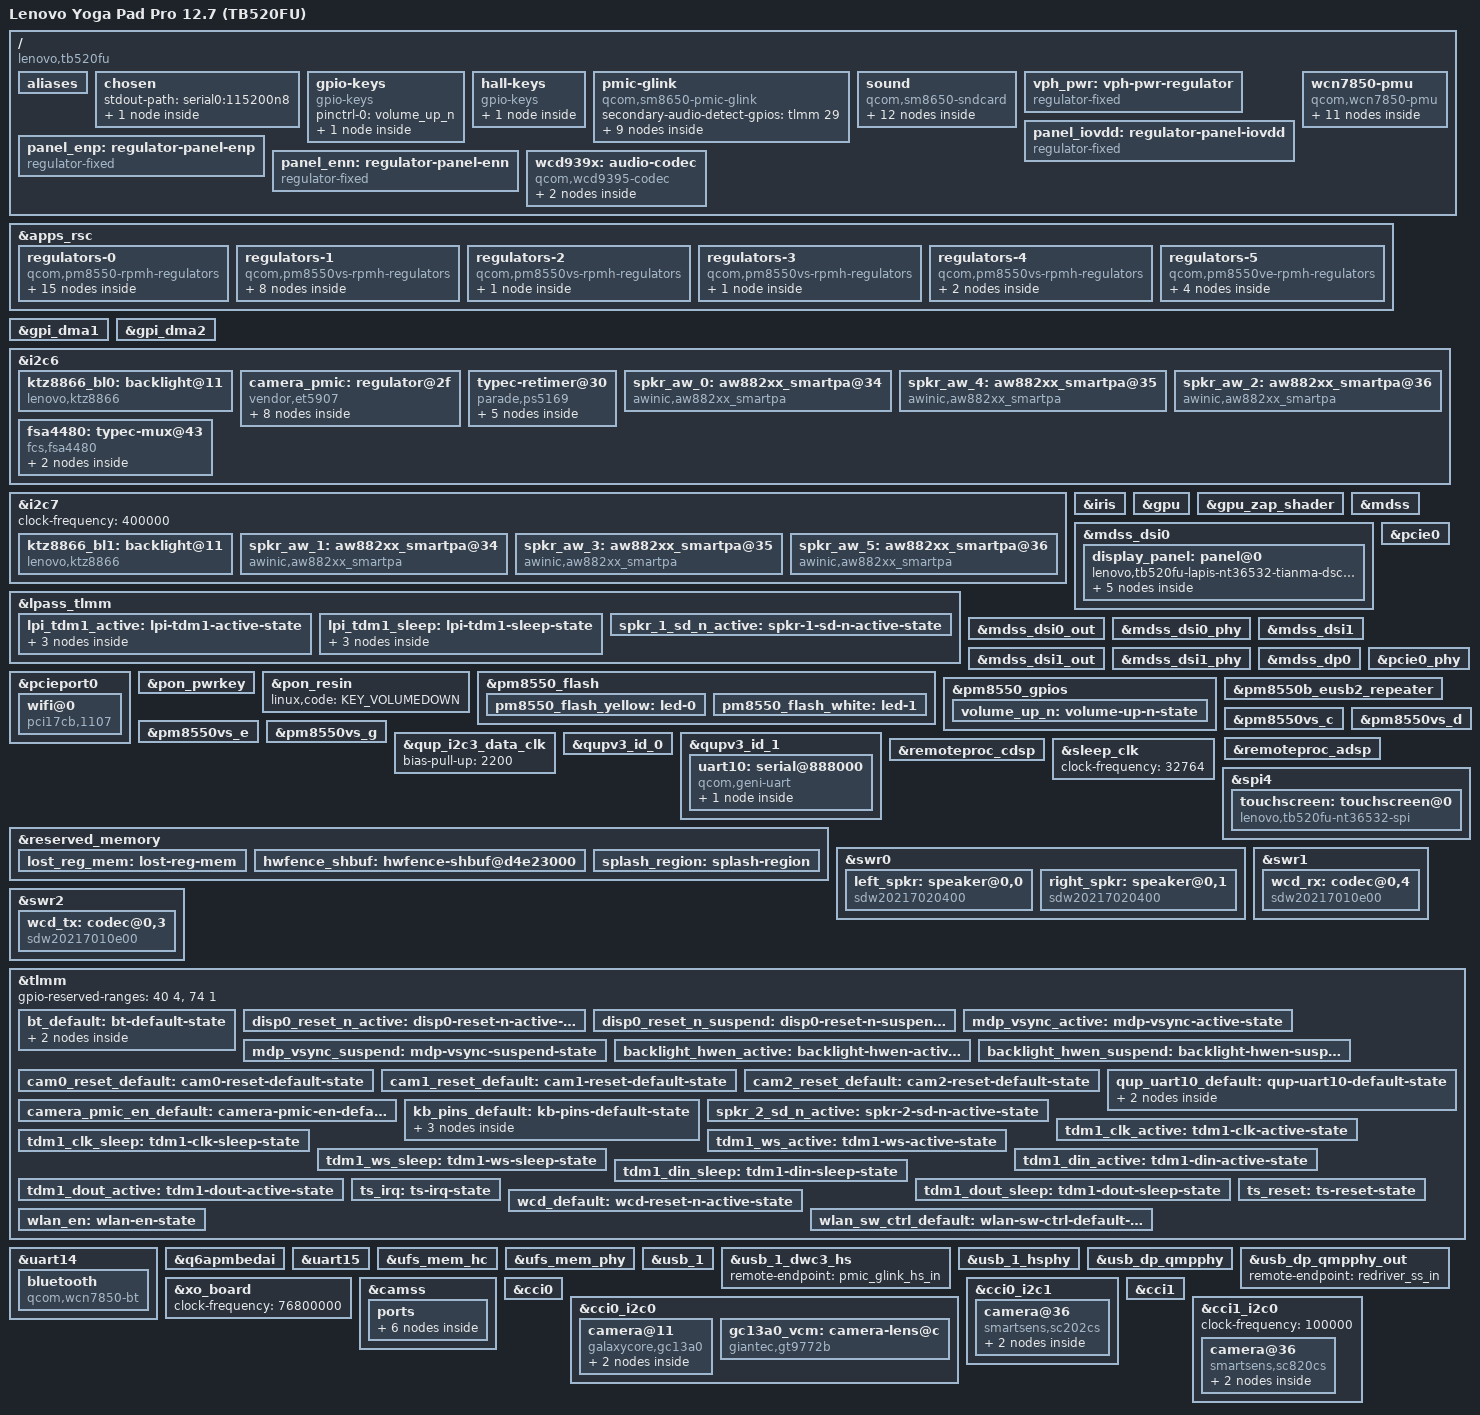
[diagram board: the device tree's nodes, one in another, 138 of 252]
// SPDX-License-Identifier: BSD-3-Clause
/*
 * Device Tree for Lenovo Yoga Pad Pro 12.7 / Yoga Tab Plus (TB520FU, "Lapis")
 * Based on Qualcomm SM8650 (Pineapple) and Lenovo TB321FU Mainline Linux port.
 */

/dts-v1/;

#include <dt-bindings/leds/common.h>
#include <dt-bindings/regulator/qcom,rpmh-regulator.h>
#include <dt-bindings/phy/phy.h>
#include "sm8650.dtsi"
#include "pm8550.dtsi"
#include "pm8550b.dtsi"
#define PMK8550VE_SID 8
#include "pm8550ve.dtsi"
#include "pm8550vs.dtsi"
#include "pmk8550.dtsi"

/delete-node/ &rmtfs_mem;
/delete-node/ &hwfence_shbuf;
/delete-node/ &remoteproc_mpss;
/delete-node/ &qlink_logging_mem;
/delete-node/ &mpss_dsm_mem;
/delete-node/ &mpss_dsm_mem_2;
/delete-node/ &mpss_mem;
/delete-node/ &q6_mpss_dtb_mem;

/ {
	model = "Lenovo Yoga Pad Pro 12.7 (TB520FU)";
	compatible = "lenovo,tb520fu", "qcom,sm8650";
	chassis-type = "tablet";

	aliases {
		serial0 = &uart15;
		serial1 = &uart14;
		serial2 = &uart10;
	};

	chosen {
		#address-cells = <2>;
		#size-cells = <2>;
		ranges;

		stdout-path = "serial0:115200n8";

		/*
		 * Bootloader-initialized continuous splash framebuffer
		 * (2944x1840 @ 120Hz/144Hz native-landscape video-mode panel).
		 * Provides immediate display output via simpledrm before msm_drm takes over.
		 */
		framebuffer0: framebuffer@d5100000 {
			compatible = "simple-framebuffer";
			reg = <0x0 0xd5100000 0x0 0x02b00000>;
			width = <2944>;
			height = <1840>;
			stride = <(2944 * 4)>;
			format = "a8r8g8b8";
			memory-region = <&splash_region>;
		};
	};

	gpio-keys {
		compatible = "gpio-keys";

		pinctrl-0 = <&volume_up_n>;
		pinctrl-names = "default";

		key-volume-up {
			label = "Volume Up";
			linux,code = <KEY_VOLUMEUP>;
			gpios = <&pm8550_gpios 6 GPIO_ACTIVE_LOW>;
			debounce-interval = <15>;
			linux,can-disable;
			wakeup-source;
		};
	};

	/* Hall sensors for folio cover / stand detection (GPIO 177 & GPIO 182) */
	hall-keys {
		compatible = "gpio-keys";

		switch-hall0 {
			label = "Hall Sensor 0";
			linux,input-type = <EV_SW>;
			linux,code = <SW_TABLET_MODE>;
			gpios = <&tlmm 177 GPIO_ACTIVE_LOW>;
			debounce-interval = <20>;
			wakeup-source;
		};
	};

	/* TB520FU has a single USB-C 3.2 Gen 1 port (connector@0) */
	pmic-glink {
		compatible = "qcom,sm8650-pmic-glink",
			     "qcom,sm8550-pmic-glink",
			     "qcom,pmic-glink";
		#address-cells = <1>;
		#size-cells = <0>;
		secondary-audio-detect-gpios = <&tlmm 29 GPIO_ACTIVE_HIGH>;

		connector@0 {
			compatible = "usb-c-connector";
			reg = <0>;

			power-role = "dual";
			data-role = "dual";
			self-powered;

			ports {
				#address-cells = <1>;
				#size-cells = <0>;

				port@0 {
					reg = <0>;

					pmic_glink_hs_in: endpoint {
						remote-endpoint = <&usb_1_dwc3_hs>;
					};
				};

				port@1 {
					reg = <1>;

					pmic_glink_ss_in: endpoint {
						remote-endpoint = <&redriver_ss_out>;
					};
				};

				port@2 {
					reg = <2>;
					#address-cells = <1>;
					#size-cells = <0>;

					pmic_glink_sbu: endpoint@0 {
						reg = <0>;
						remote-endpoint = <&fsa4480_sbu_mux>;
					};

					pmic_glink_sbu_codec: endpoint@1 {
						reg = <1>;
						remote-endpoint = <&wcd_codec_headset_in>;
					};
				};
			};
		};
	};

	sound {
		compatible = "qcom,sm8650-sndcard", "qcom,sm8450-sndcard";
		model = "Lenovo-YogaPadPro-TB520FU";
		pinctrl-names = "default", "sleep";
		pinctrl-0 = <&tdm1_clk_active>, <&tdm1_ws_active>,
			    <&tdm1_din_active>, <&tdm1_dout_active>;
		pinctrl-1 = <&tdm1_clk_sleep>, <&tdm1_ws_sleep>,
			    <&tdm1_din_sleep>, <&tdm1_dout_sleep>;
		audio-routing = "IN1_HPHL", "HPHL_OUT",
				"IN2_HPHR", "HPHR_OUT",
				"AMIC1", "MIC BIAS1",
				"AMIC2", "MIC BIAS2",
				"AMIC3", "MIC BIAS3",
				"AMIC4", "MIC BIAS3",
				"AMIC5", "MIC BIAS4",
				"TX SWR_INPUT0", "ADC1_OUTPUT",
				"TX SWR_INPUT1", "ADC2_OUTPUT",
				"TX SWR_INPUT2", "ADC3_OUTPUT",
				"TX SWR_INPUT3", "ADC4_OUTPUT";

		wcd-playback-dai-link {
			link-name = "WCD Playback";

			cpu {
				sound-dai = <&q6apmbedai RX_CODEC_DMA_RX_0>;
			};

			codec {
				sound-dai = <&wcd939x 0>, <&swr1 0>, <&lpass_rxmacro 0>;
			};

			platform {
				sound-dai = <&q6apm>;
			};
		};

		wcd-capture-dai-link {
			link-name = "WCD Capture";

			cpu {
				sound-dai = <&q6apmbedai TX_CODEC_DMA_TX_3>;
			};

			codec {
				sound-dai = <&wcd939x 1>, <&swr2 0>, <&lpass_txmacro 0>;
			};

			platform {
				sound-dai = <&q6apm>;
			};
		};

		/* 6x Awinic AW88261 SmartPA speaker array (3 on I2C6 + 3 on I2C7) */
		aw-spk-dai-link {
			link-name = "AW882xx Playback";

			cpu {
				sound-dai = <&q6apmbedai SECONDARY_TDM_RX_0>;
			};

			codec {
				sound-dai = <&spkr_aw_0>, <&spkr_aw_1>,
					    <&spkr_aw_2>, <&spkr_aw_3>,
					    <&spkr_aw_4>, <&spkr_aw_5>;
			};

			platform {
				sound-dai = <&q6apm>;
			};
		};
	};

	vph_pwr: vph-pwr-regulator {
		compatible = "regulator-fixed";

		regulator-name = "vph_pwr";
		regulator-min-microvolt = <3700000>;
		regulator-max-microvolt = <3700000>;

		regulator-always-on;
		regulator-boot-on;
	};

	panel_iovdd: regulator-panel-iovdd {
		compatible = "regulator-fixed";
		regulator-name = "panel_iovdd";
		regulator-min-microvolt = <1800000>;
		regulator-max-microvolt = <1800000>;
		gpio = <&pm8550ve_gpios 8 GPIO_ACTIVE_HIGH>;
		enable-active-high;
	};

	panel_enp: regulator-panel-enp {
		compatible = "regulator-fixed";
		regulator-name = "panel_enp";
		gpio = <&tlmm 72 GPIO_ACTIVE_HIGH>;
		enable-active-high;
	};

	panel_enn: regulator-panel-enn {
		compatible = "regulator-fixed";
		regulator-name = "panel_enn";
		gpio = <&tlmm 73 GPIO_ACTIVE_HIGH>;
		enable-active-high;
	};

	wcd939x: audio-codec {
		compatible = "qcom,wcd9395-codec", "qcom,wcd9390-codec";

		pinctrl-0 = <&wcd_default>;
		pinctrl-names = "default";

		qcom,micbias1-microvolt = <1800000>;
		qcom,micbias2-microvolt = <1800000>;
		qcom,micbias3-microvolt = <1800000>;
		qcom,micbias4-microvolt = <1800000>;
		qcom,mbhc-buttons-vthreshold-microvolt = <75000 150000 237000 500000 500000 500000 500000 500000>;
		qcom,mbhc-headset-vthreshold-microvolt = <1700000>;
		qcom,mbhc-headphone-vthreshold-microvolt = <50000>;
		qcom,rx-device = <&wcd_rx>;
		qcom,tx-device = <&wcd_tx>;

		reset-gpios = <&tlmm 107 GPIO_ACTIVE_LOW>;

		vdd-buck-supply = <&vreg_l15b_1p8>;
		vdd-rxtx-supply = <&vreg_l15b_1p8>;
		vdd-io-supply = <&vreg_l15b_1p8>;
		vdd-mic-bias-supply = <&vreg_bob1>;

		#sound-dai-cells = <1>;

		mode-switch;
		orientation-switch;

		port {
			#address-cells = <1>;
			#size-cells = <0>;

			wcd_codec_headset_in: endpoint@0 {
				reg = <0>;
				remote-endpoint = <&pmic_glink_sbu_codec>;
			};
		};
	};

	wcn7850-pmu {
		compatible = "qcom,wcn7850-pmu";

		pinctrl-names = "default";
		pinctrl-0 = <&wlan_en>, <&bt_default>, <&wlan_sw_ctrl_default>;

		wlan-enable-gpios = <&tlmm 16 GPIO_ACTIVE_HIGH>;
		bt-enable-gpios = <&tlmm 17 GPIO_ACTIVE_HIGH>;

		vdd-supply = <&vreg_s4i_0p85>;
		vddio-supply = <&vreg_l15b_1p8>;
		vddio1p2-supply = <&vreg_l3c_1p2>;
		vddaon-supply = <&vreg_s2c_0p8>;
		vdddig-supply = <&vreg_s3c_0p9>;
		vddrfa1p2-supply = <&vreg_s1c_1p2>;
		vddrfa1p8-supply = <&vreg_s6c_1p8>;

		clocks = <&rpmhcc RPMH_RF_CLK1>;

		regulators {
			vreg_pmu_rfa_cmn: ldo0 {
				regulator-name = "vreg_pmu_rfa_cmn";
			};

			vreg_pmu_aon_0p59: ldo1 {
				regulator-name = "vreg_pmu_aon_0p59";
			};

			vreg_pmu_wlcx_0p8: ldo2 {
				regulator-name = "vreg_pmu_wlcx_0p8";
			};

			vreg_pmu_wlmx_0p85: ldo3 {
				regulator-name = "vreg_pmu_wlmx_0p85";
			};

			vreg_pmu_btcmx_0p85: ldo4 {
				regulator-name = "vreg_pmu_btcmx_0p85";
			};

			vreg_pmu_rfa_0p8: ldo5 {
				regulator-name = "vreg_pmu_rfa_0p8";
			};

			vreg_pmu_rfa_1p2: ldo6 {
				regulator-name = "vreg_pmu_rfa_1p2";
			};

			vreg_pmu_rfa_1p8: ldo7 {
				regulator-name = "vreg_pmu_rfa_1p8";
			};

			vreg_pmu_pcie_0p9: ldo8 {
				regulator-name = "vreg_pmu_pcie_0p9";
			};

			vreg_pmu_pcie_1p8: ldo9 {
				regulator-name = "vreg_pmu_pcie_1p8";
			};
		};
	};
};

&apps_rsc {
	regulators-0 {
		compatible = "qcom,pm8550-rpmh-regulators";

		vdd-bob1-supply = <&vph_pwr>;
		vdd-bob2-supply = <&vph_pwr>;
		vdd-l1-l4-l10-supply = <&vreg_s6c_1p8>;
		vdd-l2-l13-l14-supply = <&vreg_bob1>;
		vdd-l3-supply = <&vreg_s1c_1p2>;
		vdd-l5-l16-supply = <&vreg_bob1>;
		vdd-l6-l7-supply = <&vreg_bob1>;
		vdd-l8-l9-supply = <&vreg_bob1>;
		vdd-l11-supply = <&vreg_s1c_1p2>;
		vdd-l12-supply = <&vreg_s6c_1p8>;
		vdd-l15-supply = <&vreg_s6c_1p8>;
		vdd-l17-supply = <&vreg_bob2>;

		qcom,pmic-id = "b";

		vreg_bob1: bob1 {
			regulator-name = "vreg_bob1";
			regulator-min-microvolt = <3296000>;
			regulator-max-microvolt = <3960000>;
			regulator-initial-mode = <RPMH_REGULATOR_MODE_HPM>;
		};

		vreg_bob2: bob2 {
			regulator-name = "vreg_bob2";
			regulator-min-microvolt = <2720000>;
			regulator-max-microvolt = <3008000>;
			regulator-initial-mode = <RPMH_REGULATOR_MODE_HPM>;
		};

		vreg_l2b_3p0: ldo2 {
			regulator-name = "vreg_l2b_3p0";
			regulator-min-microvolt = <3008000>;
			regulator-max-microvolt = <3008000>;
			regulator-initial-mode = <RPMH_REGULATOR_MODE_HPM>;
			regulator-allow-set-load;
			regulator-allowed-modes = <RPMH_REGULATOR_MODE_LPM
						   RPMH_REGULATOR_MODE_HPM>;
		};

		vreg_l5b_3p1: ldo5 {
			regulator-name = "vreg_l5b_3p1";
			regulator-min-microvolt = <3104000>;
			regulator-max-microvolt = <3104000>;
			regulator-initial-mode = <RPMH_REGULATOR_MODE_HPM>;
			regulator-allow-set-load;
			regulator-allowed-modes = <RPMH_REGULATOR_MODE_LPM
						   RPMH_REGULATOR_MODE_HPM>;
		};

		vreg_l6b_1p8: ldo6 {
			regulator-name = "vreg_l6b_1p8";
			regulator-min-microvolt = <1800000>;
			regulator-max-microvolt = <3008000>;
			regulator-initial-mode = <RPMH_REGULATOR_MODE_HPM>;
			regulator-allow-set-load;
			regulator-allowed-modes = <RPMH_REGULATOR_MODE_LPM
						   RPMH_REGULATOR_MODE_HPM>;
		};

		vreg_l7b_1p8: ldo7 {
			regulator-name = "vreg_l7b_1p8";
			regulator-min-microvolt = <1800000>;
			regulator-max-microvolt = <3008000>;
			regulator-initial-mode = <RPMH_REGULATOR_MODE_HPM>;
		};

		vreg_l8b_1p8: ldo8 {
			regulator-name = "vreg_l8b_1p8";
			regulator-min-microvolt = <1800000>;
			regulator-max-microvolt = <3008000>;
			regulator-initial-mode = <RPMH_REGULATOR_MODE_HPM>;
			regulator-allow-set-load;
			regulator-allowed-modes = <RPMH_REGULATOR_MODE_LPM
						   RPMH_REGULATOR_MODE_HPM>;
		};

		vreg_l10b_1p8: ldo10 {
			regulator-name = "vreg_l10b_1p8";
			regulator-min-microvolt = <1800000>;
			regulator-max-microvolt = <1800000>;
			regulator-initial-mode = <RPMH_REGULATOR_MODE_HPM>;
			regulator-allow-set-load;
			regulator-boot-on;
			regulator-always-on;
			regulator-allowed-modes = <RPMH_REGULATOR_MODE_LPM
						   RPMH_REGULATOR_MODE_HPM>;
		};

		vreg_l11b_1p2: ldo11 {
			regulator-name = "vreg_l11b_1p2";
			regulator-min-microvolt = <1200000>;
			regulator-max-microvolt = <1504000>;
			regulator-initial-mode = <RPMH_REGULATOR_MODE_HPM>;
			regulator-allow-set-load;
			regulator-allowed-modes = <RPMH_REGULATOR_MODE_LPM
						   RPMH_REGULATOR_MODE_HPM>;
		};

		vreg_l12b_1p8: ldo12 {
			regulator-name = "vreg_l12b_1p8";
			regulator-min-microvolt = <1800000>;
			regulator-max-microvolt = <1800000>;
			regulator-initial-mode = <RPMH_REGULATOR_MODE_HPM>;
			regulator-allow-set-load;
			regulator-allowed-modes = <RPMH_REGULATOR_MODE_LPM
						   RPMH_REGULATOR_MODE_HPM>;
		};

		vreg_l13b_3p0: ldo13 {
			regulator-name = "vreg_l13b_3p0";
			regulator-min-microvolt = <3000000>;
			regulator-max-microvolt = <3000000>;
			regulator-initial-mode = <RPMH_REGULATOR_MODE_HPM>;
			regulator-allow-set-load;
			regulator-allowed-modes = <RPMH_REGULATOR_MODE_LPM
						   RPMH_REGULATOR_MODE_HPM>;
		};

		vreg_l14b_3p2: ldo14 {
			regulator-name = "vreg_l14b_3p2";
			regulator-min-microvolt = <3200000>;
			regulator-max-microvolt = <3200000>;
			regulator-initial-mode = <RPMH_REGULATOR_MODE_HPM>;
			regulator-allow-set-load;
			regulator-allowed-modes = <RPMH_REGULATOR_MODE_LPM
						   RPMH_REGULATOR_MODE_HPM>;
		};

		vreg_l15b_1p8: ldo15 {
			regulator-name = "vreg_l15b_1p8";
			regulator-min-microvolt = <1800000>;
			regulator-max-microvolt = <1800000>;
			regulator-initial-mode = <RPMH_REGULATOR_MODE_HPM>;
			regulator-allow-set-load;
			regulator-allowed-modes = <RPMH_REGULATOR_MODE_LPM
						   RPMH_REGULATOR_MODE_HPM>;
		};

		vreg_l16b_2p8: ldo16 {
			regulator-name = "vreg_l16b_2p8";
			regulator-min-microvolt = <2800000>;
			regulator-max-microvolt = <2800000>;
			regulator-initial-mode = <RPMH_REGULATOR_MODE_HPM>;
			regulator-allow-set-load;
			regulator-allowed-modes = <RPMH_REGULATOR_MODE_LPM
						   RPMH_REGULATOR_MODE_HPM>;
		};

		vreg_l17b_2p5: ldo17 {
			regulator-name = "vreg_l17b_2p5";
			regulator-min-microvolt = <2504000>;
			regulator-max-microvolt = <2504000>;
			regulator-initial-mode = <RPMH_REGULATOR_MODE_HPM>;
			regulator-allow-set-load;
			regulator-allowed-modes = <RPMH_REGULATOR_MODE_LPM
						   RPMH_REGULATOR_MODE_HPM>;
		};
	};

	regulators-1 {
		compatible = "qcom,pm8550vs-rpmh-regulators";

		vdd-l1-supply = <&vreg_s1c_1p2>;
		vdd-l2-supply = <&vreg_s1c_1p2>;
		vdd-l3-supply = <&vreg_s1c_1p2>;
		vdd-s1-supply = <&vph_pwr>;
		vdd-s2-supply = <&vph_pwr>;
		vdd-s3-supply = <&vph_pwr>;
		vdd-s4-supply = <&vph_pwr>;
		vdd-s5-supply = <&vph_pwr>;
		vdd-s6-supply = <&vph_pwr>;

		qcom,pmic-id = "c";

		vreg_s1c_1p2: smps1 {
			regulator-name = "vreg_s1c_1p2";
			regulator-min-microvolt = <1256000>;
			regulator-max-microvolt = <1348000>;
			regulator-initial-mode = <RPMH_REGULATOR_MODE_HPM>;
		};

		vreg_s2c_0p8: smps2 {
			regulator-name = "vreg_s2c_0p8";
			regulator-min-microvolt = <852000>;
			regulator-max-microvolt = <1036000>;
			regulator-initial-mode = <RPMH_REGULATOR_MODE_HPM>;
		};

		vreg_s3c_0p9: smps3 {
			regulator-name = "vreg_s3c_0p9";
			regulator-min-microvolt = <976000>;
			regulator-max-microvolt = <1064000>;
			regulator-initial-mode = <RPMH_REGULATOR_MODE_HPM>;
		};

		vreg_s4c_1p2: smps4 {
			regulator-name = "vreg_s4c_1p2";
			regulator-min-microvolt = <1224000>;
			regulator-max-microvolt = <1280000>;
			regulator-initial-mode = <RPMH_REGULATOR_MODE_HPM>;
		};

		vreg_s5c_0p7: smps5 {
			regulator-name = "vreg_s5c_0p7";
			regulator-min-microvolt = <752000>;
			regulator-max-microvolt = <900000>;
			regulator-initial-mode = <RPMH_REGULATOR_MODE_HPM>;
		};

		vreg_s6c_1p8: smps6 {
			regulator-name = "vreg_s6c_1p8";
			regulator-min-microvolt = <1856000>;
			regulator-max-microvolt = <2000000>;
			regulator-initial-mode = <RPMH_REGULATOR_MODE_HPM>;
		};

		vreg_l1c_1p2: ldo1 {
			regulator-name = "vreg_l1c_1p2";
			regulator-min-microvolt = <1200000>;
			regulator-max-microvolt = <1200000>;
			regulator-initial-mode = <RPMH_REGULATOR_MODE_HPM>;
			regulator-allow-set-load;
			regulator-allowed-modes = <RPMH_REGULATOR_MODE_LPM
						   RPMH_REGULATOR_MODE_HPM>;
		};

		vreg_l3c_1p2: ldo3 {
			regulator-name = "vreg_l3c_1p2";
			regulator-min-microvolt = <1200000>;
			regulator-max-microvolt = <1200000>;
			regulator-initial-mode = <RPMH_REGULATOR_MODE_HPM>;
			regulator-allow-set-load;
			regulator-allowed-modes = <RPMH_REGULATOR_MODE_LPM
						   RPMH_REGULATOR_MODE_HPM>;
		};
	};

	regulators-2 {
		compatible = "qcom,pm8550vs-rpmh-regulators";

		vdd-l1-supply = <&vreg_s3c_0p9>;

		qcom,pmic-id = "d";

		vreg_l1d_0p88: ldo1 {
			regulator-name = "vreg_l1d_0p88";
			regulator-min-microvolt = <912000>;
			regulator-max-microvolt = <920000>;
			regulator-initial-mode = <RPMH_REGULATOR_MODE_HPM>;
			regulator-allow-set-load;
			regulator-allowed-modes = <RPMH_REGULATOR_MODE_LPM
						   RPMH_REGULATOR_MODE_HPM>;
		};
	};

	regulators-3 {
		compatible = "qcom,pm8550vs-rpmh-regulators";

		vdd-l3-supply = <&vreg_s3c_0p9>;

		qcom,pmic-id = "e";

		vreg_l3e_0p9: ldo3 {
			regulator-name = "vreg_l3e_0p9";
			regulator-min-microvolt = <880000>;
			regulator-max-microvolt = <920000>;
			regulator-initial-mode = <RPMH_REGULATOR_MODE_HPM>;
			regulator-allow-set-load;
			regulator-allowed-modes = <RPMH_REGULATOR_MODE_LPM
						   RPMH_REGULATOR_MODE_HPM>;
		};
	};

	regulators-4 {
		compatible = "qcom,pm8550vs-rpmh-regulators";

		vdd-l1-supply = <&vreg_s3c_0p9>;
		vdd-l3-supply = <&vreg_s3c_0p9>;

		qcom,pmic-id = "g";

		vreg_l1g_0p91: ldo1 {
			regulator-name = "vreg_l1g_0p91";
			regulator-min-microvolt = <912000>;
			regulator-max-microvolt = <920000>;
			regulator-initial-mode = <RPMH_REGULATOR_MODE_HPM>;
			regulator-allow-set-load;
			regulator-allowed-modes = <RPMH_REGULATOR_MODE_LPM
						   RPMH_REGULATOR_MODE_HPM>;
		};

		vreg_l3g_0p91: ldo3 {
			regulator-name = "vreg_l3g_0p91";
			regulator-min-microvolt = <880000>;
			regulator-max-microvolt = <912000>;
			regulator-initial-mode = <RPMH_REGULATOR_MODE_HPM>;
			regulator-allow-set-load;
			regulator-allowed-modes = <RPMH_REGULATOR_MODE_LPM
						   RPMH_REGULATOR_MODE_HPM>;
		};
	};

	regulators-5 {
		compatible = "qcom,pm8550ve-rpmh-regulators";

		vdd-l1-supply = <&vreg_s3c_0p9>;
		vdd-l2-supply = <&vreg_s3c_0p9>;
		vdd-l3-supply = <&vreg_s1c_1p2>;
		vdd-s4-supply = <&vph_pwr>;

		qcom,pmic-id = "i";

		vreg_s4i_0p85: smps4 {
			regulator-name = "vreg_s4i_0p85";
			regulator-min-microvolt = <852000>;
			regulator-max-microvolt = <1004000>;
			regulator-initial-mode = <RPMH_REGULATOR_MODE_HPM>;
		};

		vreg_l1i_0p88: ldo1 {
			regulator-name = "vreg_l1i_0p88";
			regulator-min-microvolt = <880000>;
			regulator-max-microvolt = <912000>;
			regulator-initial-mode = <RPMH_REGULATOR_MODE_HPM>;
			regulator-allow-set-load;
			regulator-allowed-modes = <RPMH_REGULATOR_MODE_LPM
						   RPMH_REGULATOR_MODE_HPM>;
		};

		vreg_l2i_0p88: ldo2 {
			regulator-name = "vreg_l2i_0p88";
			regulator-min-microvolt = <880000>;
			regulator-max-microvolt = <912000>;
			regulator-initial-mode = <RPMH_REGULATOR_MODE_HPM>;
			regulator-allow-set-load;
			regulator-allowed-modes = <RPMH_REGULATOR_MODE_LPM
						   RPMH_REGULATOR_MODE_HPM>;
		};

		vreg_l3i_1p2: ldo3 {
			regulator-name = "vreg_l3i_0p91";
			regulator-min-microvolt = <1200000>;
			regulator-max-microvolt = <1200000>;
			regulator-initial-mode = <RPMH_REGULATOR_MODE_HPM>;
			regulator-allow-set-load;
			regulator-allowed-modes = <RPMH_REGULATOR_MODE_LPM
						   RPMH_REGULATOR_MODE_HPM>;
		};
	};
};

&gpi_dma1 {
	status = "okay";
};

&gpi_dma2 {
	status = "okay";
};

/*
 * Mainline &i2c6 = i2c@a98000 (Downstream i2c14):
 *   - Primary KTZ8866 backlight (@11, HWEN GPIO 82)
 *   - 3x Awinic AW88261 SmartPA (@34 ch0, @35 ch4, @36 ch2, reset GPIO 128)
 *   - USB-C muxes (fsa4480 @42/@43) & PS5169 retimer (@30)
 *   - Camera PMIC WL2868C (@2f, enable GPIO 5)
 */
&i2c6 {
	status = "okay";

	ktz8866_bl0: backlight@11 {
		compatible = "lenovo,ktz8866", "kinetic,ktz8866";
		reg = <0x11>;

		pinctrl-0 = <&backlight_hwen_active>;
		pinctrl-1 = <&backlight_hwen_suspend>;
		pinctrl-names = "default", "sleep";
		enable-gpios = <&tlmm 82 GPIO_ACTIVE_HIGH>;

		kinetic,enable-lcd-bias;
		lenovo,companion-backlight = <&ktz8866_bl1>;
		current-num-sinks = <6>;
		max-brightness = <2047>;
		default-brightness-level = <1027>;
	};

	camera_pmic: regulator@2f {
		compatible = "vendor,et5907", "willsemi,wl2868c";
		reg = <0x2f>;

		pinctrl-0 = <&camera_pmic_en_default>;
		pinctrl-names = "default";
		enable-gpios = <&tlmm 5 GPIO_ACTIVE_HIGH>;

		vin1-supply = <&vreg_s6c_1p8>;
		vin2-supply = <&vreg_bob1>;
		vin3-supply = <&vreg_l10b_1p8>;

		regulators {
			cam_ldo1_1p2: ldo1 {
				regulator-name = "cam_ldo1_1p2";
				regulator-min-microvolt = <1200000>;
				regulator-max-microvolt = <1200000>;
			};

			cam_ldo2_1p31: ldo2 {
				regulator-name = "cam_ldo2_1p31";
				regulator-min-microvolt = <1312000>;
				regulator-max-microvolt = <1312000>;
			};

			cam_ldo3_1p8: ldo3 {
				regulator-name = "cam_ldo3_1p8";
				regulator-min-microvolt = <1800000>;
				regulator-max-microvolt = <2784000>;
			};

			cam_ldo4_2p8: ldo4 {
				regulator-name = "cam_ldo4_2p8";
				regulator-min-microvolt = <2800000>;
				regulator-max-microvolt = <2800000>;
			};

			cam_ldo5_2p78: ldo5 {
				regulator-name = "cam_ldo5_2p78";
				regulator-min-microvolt = <2784000>;
				regulator-max-microvolt = <2784000>;
				regulator-enable-ramp-delay = <10000>;
			};

			cam_ldo6_2p78: ldo6 {
				regulator-name = "cam_ldo6_2p78";
				regulator-min-microvolt = <2784000>;
				regulator-max-microvolt = <2784000>;
			};

			cam_ldo7_2p024: ldo7 {
				regulator-name = "cam_ldo7_2p024";
				regulator-min-microvolt = <2024000>;
				regulator-max-microvolt = <2024000>;
			};
		};
	};

	typec-retimer@30 {
		compatible = "parade,ps5169", "hq_redriver,ps5169";
		reg = <0x30>;

		retimer-switch;
		orientation-switch;

		ports {
			#address-cells = <1>;
			#size-cells = <0>;

			port@0 {
				reg = <0>;

				redriver_ss_out: endpoint {
					remote-endpoint = <&pmic_glink_ss_in>;
				};
			};

			port@1 {
				reg = <1>;

				redriver_ss_in: endpoint {
					data-lanes = <3 2 1 0>;
					remote-endpoint = <&usb_dp_qmpphy_out>;
				};
			};
		};
	};

	spkr_aw_0: aw882xx_smartpa@34 {
		compatible = "awinic,aw882xx_smartpa";
		reg = <0x34>;
		#sound-dai-cells = <0>;
		aw-cali-mode = "none";
		aw-re-max = <0x7530>;
		aw-re-min = <0x0fa0>;
		rename-flag = <1>;
		sound-channel = <0>;
		sync-load = <1>;
		one_rst_flag = <1>;
		reset-gpio = <&tlmm 128 GPIO_ACTIVE_HIGH>;
	};

	spkr_aw_4: aw882xx_smartpa@35 {
		compatible = "awinic,aw882xx_smartpa";
		reg = <0x35>;
		#sound-dai-cells = <0>;
		aw-cali-mode = "none";
		aw-re-max = <0x7530>;
		aw-re-min = <0x0fa0>;
		rename-flag = <1>;
		sound-channel = <4>;
		sync-load = <1>;
		one_rst_flag = <1>;
		reset-gpio = <&tlmm 128 GPIO_ACTIVE_HIGH>;
	};

	spkr_aw_2: aw882xx_smartpa@36 {
		compatible = "awinic,aw882xx_smartpa";
		reg = <0x36>;
		#sound-dai-cells = <0>;
		aw-cali-mode = "none";
		aw-re-max = <0x7530>;
		aw-re-min = <0x0fa0>;
		rename-flag = <1>;
		sound-channel = <2>;
		sync-load = <1>;
		one_rst_flag = <1>;
		reset-gpio = <&tlmm 128 GPIO_ACTIVE_HIGH>;
	};

	fsa4480: typec-mux@43 {
		compatible = "fcs,fsa4480";
		reg = <0x43>;

		vcc-supply = <&vreg_l15b_1p8>;

		mode-switch;
		orientation-switch;

		port {
			fsa4480_sbu_mux: endpoint {
				remote-endpoint = <&pmic_glink_sbu>;
			};
		};
	};
};

/*
 * Mainline &i2c7 = i2c@a9c000 (Downstream i2c15):
 *   - Secondary KTZ8866 backlight (@11)
 *   - 3x Awinic AW88261 SmartPA (@34 ch1, @35 ch3, @36 ch5, reset GPIO 28)
 */
&i2c7 {
	status = "okay";
	clock-frequency = <400000>;

	ktz8866_bl1: backlight@11 {
		compatible = "lenovo,ktz8866", "kinetic,ktz8866";
		reg = <0x11>;

		lenovo,secondary-chip;
		current-num-sinks = <6>;
		max-brightness = <2047>;
		default-brightness-level = <1027>;
	};

	spkr_aw_1: aw882xx_smartpa@34 {
		compatible = "awinic,aw882xx_smartpa";
		reg = <0x34>;
		#sound-dai-cells = <0>;
		aw-cali-mode = "none";
		aw-re-max = <0x7530>;
		aw-re-min = <0x0fa0>;
		rename-flag = <1>;
		sound-channel = <1>;
		sync-load = <1>;
		one_rst_flag = <2>;
		reset-gpio = <&tlmm 28 GPIO_ACTIVE_HIGH>;
	};

	spkr_aw_3: aw882xx_smartpa@35 {
		compatible = "awinic,aw882xx_smartpa";
		reg = <0x35>;
		#sound-dai-cells = <0>;
		aw-cali-mode = "none";
		aw-re-max = <0x7530>;
		aw-re-min = <0x0fa0>;
		rename-flag = <1>;
		sound-channel = <3>;
		sync-load = <1>;
		one_rst_flag = <2>;
		reset-gpio = <&tlmm 28 GPIO_ACTIVE_HIGH>;
	};

	spkr_aw_5: aw882xx_smartpa@36 {
		compatible = "awinic,aw882xx_smartpa";
		reg = <0x36>;
		#sound-dai-cells = <0>;
		aw-cali-mode = "none";
		aw-re-max = <0x7530>;
		aw-re-min = <0x0fa0>;
		rename-flag = <1>;
		sound-channel = <5>;
		sync-load = <1>;
		one_rst_flag = <2>;
		reset-gpio = <&tlmm 28 GPIO_ACTIVE_HIGH>;
	};
};

&iris {
	status = "okay";
};

&gpu {
	status = "okay";
};

&gpu_zap_shader {
	firmware-name = "qcom/sm8650/lenovo/tb520fu/gen70900_zap.mbn";
};

&lpass_tlmm {
	lpi_tdm1_active: lpi-tdm1-active-state {
		clk-pins {
			pins = "gpio6";
			function = "i2s1_clk";
			drive-strength = <8>;
			bias-disable;
			output-high;
		};

		ws-pins {
			pins = "gpio7";
			function = "i2s1_ws";
			drive-strength = <8>;
			bias-disable;
			output-high;
		};

		data-pins {
			pins = "gpio8", "gpio9";
			function = "i2s1_data";
			drive-strength = <8>;
			bias-disable;
			output-high;
		};
	};

	lpi_tdm1_sleep: lpi-tdm1-sleep-state {
		clk-pins {
			pins = "gpio6";
			function = "i2s1_clk";
			drive-strength = <2>;
			bias-pull-down;
			input-enable;
		};

		ws-pins {
			pins = "gpio7";
			function = "i2s1_ws";
			drive-strength = <2>;
			bias-pull-down;
			input-enable;
		};

		data-pins {
			pins = "gpio8", "gpio9";
			function = "i2s1_data";
			drive-strength = <2>;
			bias-pull-down;
			input-enable;
		};
	};

	spkr_1_sd_n_active: spkr-1-sd-n-active-state {
		pins = "gpio21";
		function = "gpio";
		drive-strength = <16>;
		bias-disable;
		output-low;
	};
};

&mdss {
	status = "okay";
};

&mdss_dsi0 {
	vdda-supply = <&vreg_l3i_1p2>;
	qcom,dual-dsi-mode;
	qcom,sync-dual-dsi;
	qcom,master-dsi;
	status = "okay";

	display_panel: panel@0 {
		compatible = "lenovo,tb520fu-lapis-nt36532-tianma-dsc-vid",
			     "lenovo,lapis-nt36532-tianma-dsc-vid",
			     "lenovo,tb321fu-kirby-nt36523-csot-dsc-vid",
			     "lenovo,kirby-nt36523-csot-dsc-vid";
		reg = <0>;
		panel-name = "lapis_tianma_nt36532_dsc_3k_video";
		vddio-supply = <&panel_iovdd>;
		enp-supply = <&panel_enp>;
		enn-supply = <&panel_enn>;
		reset-gpios = <&tlmm 133 GPIO_ACTIVE_LOW>;
		pinctrl-names = "default", "sleep";
		pinctrl-0 = <&disp0_reset_n_active>, <&mdp_vsync_active>;
		pinctrl-1 = <&disp0_reset_n_suspend>, <&mdp_vsync_suspend>;
		backlight = <&ktz8866_bl0>;
		rotation = <0>;

		ports {
			#address-cells = <1>;
			#size-cells = <0>;

			port@0 {
				reg = <0>;

				panel_in_0: endpoint {
					remote-endpoint = <&mdss_dsi0_out>;
				};
			};

			port@1 {
				reg = <1>;

				panel_in_1: endpoint {
					remote-endpoint = <&mdss_dsi1_out>;
				};
			};
		};
	};
};

&mdss_dsi0_out {
	data-lanes = <0 1 2 3>;
	remote-endpoint = <&panel_in_0>;
};

&mdss_dsi0_phy {
	vdds-supply = <&vreg_l1i_0p88>;
	phy-type = <PHY_TYPE_DPHY>;
	qcom,mdss-dsi-panel-phy-timings = [00 25 0a 0a 1b 18 0a 0a 0a 02 04 00 1f 0f];

	status = "okay";
};

&mdss_dsi1 {
	vdda-supply = <&vreg_l3i_1p2>;
	qcom,dual-dsi-mode;
	qcom,sync-dual-dsi;
	assigned-clock-parents = <&mdss_dsi0_phy DSI_BYTE_PLL_CLK>,
				 <&mdss_dsi0_phy DSI_PIXEL_PLL_CLK>;

	status = "okay";
};

&mdss_dsi1_out {
	data-lanes = <0 1 2 3>;
	remote-endpoint = <&panel_in_1>;
};

&mdss_dsi1_phy {
	vdds-supply = <&vreg_l1i_0p88>;
	phy-type = <PHY_TYPE_DPHY>;
	qcom,mdss-dsi-panel-phy-timings = [00 25 0a 0a 1b 18 0a 0a 0a 02 04 00 1f 0f];

	status = "okay";
};

&mdss_dp0 {
	status = "okay";
};

&pcie0 {
	wake-gpios = <&tlmm 96 GPIO_ACTIVE_HIGH>;
	perst-gpios = <&tlmm 94 GPIO_ACTIVE_LOW>;

	pinctrl-0 = <&pcie0_default_state>;
	pinctrl-names = "default";

	status = "okay";
};

&pcieport0 {
	wifi@0 {
		compatible = "pci17cb,1107";
		reg = <0x10000 0x0 0x0 0x0 0x0>;

		vddrfacmn-supply = <&vreg_pmu_rfa_cmn>;
		vddaon-supply = <&vreg_pmu_aon_0p59>;
		vddwlcx-supply = <&vreg_pmu_wlcx_0p8>;
		vddwlmx-supply = <&vreg_pmu_wlmx_0p85>;
		vddrfa0p8-supply = <&vreg_pmu_rfa_0p8>;
		vddrfa1p2-supply = <&vreg_pmu_rfa_1p2>;
		vddrfa1p8-supply = <&vreg_pmu_rfa_1p8>;
		vddpcie0p9-supply = <&vreg_pmu_pcie_0p9>;
		vddpcie1p8-supply = <&vreg_pmu_pcie_1p8>;
	};
};

&pcie0_phy {
	vdda-phy-supply = <&vreg_l1i_0p88>;
	vdda-pll-supply = <&vreg_l3i_1p2>;

	status = "okay";
};

&pon_pwrkey {
	status = "okay";
};

&pon_resin {
	linux,code = <KEY_VOLUMEDOWN>;

	status = "okay";
};

&pm8550_flash {
	status = "okay";

	pm8550_flash_yellow: led-0 {
		function = LED_FUNCTION_FLASH;
		color = <LED_COLOR_ID_YELLOW>;
		led-sources = <1>, <4>;
		led-max-microamp = <500000>;
		flash-max-microamp = <2000000>;
		flash-max-timeout-us = <1280000>;
		function-enumerator = <0>;
	};

	pm8550_flash_white: led-1 {
		function = LED_FUNCTION_FLASH;
		color = <LED_COLOR_ID_WHITE>;
		led-sources = <2>, <3>;
		led-max-microamp = <500000>;
		flash-max-microamp = <2000000>;
		flash-max-timeout-us = <1280000>;
		function-enumerator = <1>;
	};
};

&pm8550_gpios {
	volume_up_n: volume-up-n-state {
		pins = "gpio6";
		function = "normal";
		bias-pull-up;
		input-enable;
		power-source = <1>;
	};
};

&pm8550b_eusb2_repeater {
	vdd18-supply = <&vreg_l15b_1p8>;
	vdd3-supply = <&vreg_l5b_3p1>;
	qcom,tune-usb2-amplitude = /bits/ 8 <0x0d>;
	qcom,tune-usb2-disc-thres = /bits/ 8 <0x06>;
	qcom,tune-usb2-preem = /bits/ 8 <0x07>;
	qcom,squelch-detector = <(-4000)>;
};

&pm8550vs_c {
	status = "okay";
};

&pm8550vs_d {
	status = "okay";
};

&pm8550vs_e {
	status = "okay";
};

&pm8550vs_g {
	status = "okay";
};

&qup_i2c3_data_clk {
	bias-pull-up = <2200>;
};

&qupv3_id_0 {
	status = "okay";
};

/*
 * Enable GENI QUPv3 Wrapper 2 (qupv3_id_1 @ 0x8c0000) and define
 * uart10 (serial@888000, SE2) for the Lenovo Pogo-Pin Magnetic Keyboard.
 */
&qupv3_id_1 {
	status = "okay";

	uart10: serial@888000 {
		compatible = "qcom,geni-uart";
		reg = <0 0x00888000 0 0x4000>;
		interrupts = <GIC_SPI 584 IRQ_TYPE_LEVEL_HIGH 0>;
		clocks = <&gcc GCC_QUPV3_WRAP2_S2_CLK>;
		clock-names = "se";

		interconnects = <&clk_virt MASTER_QUP_CORE_2 QCOM_ICC_TAG_ALWAYS
				 &clk_virt SLAVE_QUP_CORE_2 QCOM_ICC_TAG_ALWAYS>,
				<&gem_noc MASTER_APPSS_PROC QCOM_ICC_TAG_ACTIVE_ONLY
				 &config_noc SLAVE_QUP_2 QCOM_ICC_TAG_ACTIVE_ONLY>;
		interconnect-names = "qup-core",
				     "qup-config";

		power-domains = <&rpmhpd RPMHPD_CX>;
		operating-points-v2 = <&qup_opp_table_100mhz>;

		pinctrl-0 = <&qup_uart10_default>;
		pinctrl-names = "default";

		status = "okay";

		keyboard {
			compatible = "lenovo,tb520fu-keyboard",
				     "lenovo,lenovo_keyboard";

			pinctrl-0 = <&kb_pins_default>;
			pinctrl-names = "default";

			power-en-gpios = <&tlmm 173 GPIO_ACTIVE_HIGH>;
			tx-en-gpios = <&tlmm 119 GPIO_ACTIVE_HIGH>;
			plug-gpios = <&tlmm 198 GPIO_ACTIVE_HIGH>;
			uart-wake-gpios = <&tlmm 171 GPIO_ACTIVE_HIGH>;
			pupd-gpios = <&tlmm 180 GPIO_ACTIVE_HIGH>;
			lid-gpios = <&tlmm 200 GPIO_ACTIVE_HIGH>;
		};
	};
};

&remoteproc_adsp {
	firmware-name = "qcom/sm8650/lenovo/tb520fu/adsp.mdt",
			"qcom/sm8650/lenovo/tb520fu/adsp_dtb.mdt";

	status = "okay";
};

&remoteproc_cdsp {
	firmware-name = "qcom/sm8650/lenovo/tb520fu/cdsp.mdt",
			"qcom/sm8650/lenovo/tb520fu/cdsp_dtb.mdt";

	status = "okay";
};

&reserved_memory {
	lost_reg_mem: lost-reg-mem {
		reg = <0 0x9b09c000 0 0x4000>;
		no-map;
	};

	hwfence_shbuf: hwfence-shbuf@d4e23000 {
		reg = <0 0xd4e23000 0 0x2dd000>;
		no-map;
	};

	splash_region: splash-region {
		label = "cont_splash_region";
		reg = <0 0xd5100000 0 0x2b00000>;
		no-map;
	};
};

&sleep_clk {
	clock-frequency = <32764>;
};

/*
 * Mainline &spi4 = spi@a90000 (Downstream spi12):
 *   Novatek NT36532 Touchscreen + Lenovo Tab Pen Plus Stylus (1840x2944)
 */
&spi4 {
	status = "okay";

	touchscreen: touchscreen@0 {
		compatible = "lenovo,tb520fu-nt36532-spi",
			     "lenovo,tb321fu-nt36523n-spi",
			     "novatek,nt36523n-spi",
			     "novatek,NVT-ts-spi";
		reg = <0>;

		reset-gpios = <&tlmm 161 GPIO_ACTIVE_HIGH>;
		irq-gpio = <&tlmm 162 GPIO_ACTIVE_LOW>;
		novatek,reset-gpio = <&tlmm 161 GPIO_ACTIVE_HIGH>;
		novatek,irq-gpio = <&tlmm 162 GPIO_ACTIVE_LOW>;

		vdd-supply = <&vreg_l14b_3p2>;
		vio-supply = <&vreg_l12b_1p8>;

		spi-max-frequency = <9600000>;
		novatek,swrst-n8-addr = <0x03f0fe>;
		novatek,spi-rd-fast-addr = <0x03f310>;
		novatek,pen-support;

		touchscreen-size-x = <18400>;
		touchscreen-size-y = <29440>;
		touchscreen-swapped-x-y;
		touchscreen-inverted-y;

		firmware-name = "qcom/sm8650/lenovo/tb520fu/novatek_ts_fw.bin";
		panel = <&display_panel>;

		pinctrl-names = "default";
		pinctrl-0 = <&ts_reset>, <&ts_irq>;
	};
};

&swr0 {
	status = "okay";

	left_spkr: speaker@0,0 {
		compatible = "sdw20217020400";
		reg = <0 0>;
		pinctrl-0 = <&spkr_1_sd_n_active>;
		pinctrl-names = "default";
		powerdown-gpios = <&lpass_tlmm 21 GPIO_ACTIVE_LOW>;
		#sound-dai-cells = <0>;
		sound-name-prefix = "SpkrLeft";
		vdd-1p8-supply = <&vreg_l15b_1p8>;
		vdd-io-supply = <&vreg_l3c_1p2>;
		qcom,port-mapping = <1 2 3 7 10 13>;
	};

	right_spkr: speaker@0,1 {
		compatible = "sdw20217020400";
		reg = <0 1>;
		pinctrl-0 = <&spkr_2_sd_n_active>;
		pinctrl-names = "default";
		powerdown-gpios = <&tlmm 77 GPIO_ACTIVE_LOW>;
		#sound-dai-cells = <0>;
		sound-name-prefix = "SpkrRight";
		vdd-1p8-supply = <&vreg_l15b_1p8>;
		vdd-io-supply = <&vreg_l3c_1p2>;
		qcom,port-mapping = <4 5 6 7 11 13>;
	};
};

&swr1 {
	status = "okay";

	wcd_rx: codec@0,4 {
		compatible = "sdw20217010e00";
		reg = <0 4>;
		qcom,rx-port-mapping = <1 2 3 4 5 9>;
	};
};

&swr2 {
	status = "okay";

	wcd_tx: codec@0,3 {
		compatible = "sdw20217010e00";
		reg = <0 3>;
		qcom,tx-port-mapping = <2 2 3 4>;
	};
};

&tlmm {
	gpio-reserved-ranges = <40 4>, <74 1>;

	bt_default: bt-default-state {
		bt-en-pins {
			pins = "gpio17";
			function = "gpio";
			drive-strength = <16>;
			bias-disable;
		};

		sw-ctrl-pins {
			pins = "gpio18";
			function = "gpio";
			bias-pull-down;
		};
	};

	disp0_reset_n_active: disp0-reset-n-active-state {
		pins = "gpio133";
		function = "gpio";
		drive-strength = <8>;
		bias-disable;
	};

	disp0_reset_n_suspend: disp0-reset-n-suspend-state {
		pins = "gpio133";
		function = "gpio";
		drive-strength = <2>;
		bias-pull-down;
	};

	mdp_vsync_active: mdp-vsync-active-state {
		pins = "gpio86";
		function = "mdp_vsync";
		drive-strength = <2>;
		bias-pull-down;
	};

	mdp_vsync_suspend: mdp-vsync-suspend-state {
		pins = "gpio86";
		function = "gpio";
		drive-strength = <2>;
		bias-pull-down;
	};

	/* On TB520FU (Lapis), KTZ8866 HWEN is GPIO 82 (0x52) */
	backlight_hwen_active: backlight-hwen-active-state {
		pins = "gpio82";
		function = "gpio";
		drive-strength = <8>;
		bias-disable;
		output-high;
	};

	backlight_hwen_suspend: backlight-hwen-suspend-state {
		pins = "gpio82";
		function = "gpio";
		drive-strength = <2>;
		bias-pull-down;
		output-low;
	};

	/*
	 * On TB520FU (Lapis), cam0_reset is GPIO 7 (NOT GPIO 11, which is
	 * used by uart10 RX for the Pogo-Pin keyboard).
	 */
	cam0_reset_default: cam0-reset-default-state {
		pins = "gpio7";
		function = "gpio";
		drive-strength = <2>;
		bias-disable;
	};

	cam1_reset_default: cam1-reset-default-state {
		pins = "gpio109";
		function = "gpio";
		drive-strength = <2>;
		bias-disable;
	};

	cam2_reset_default: cam2-reset-default-state {
		pins = "gpio15";
		function = "gpio";
		drive-strength = <2>;
		bias-disable;
	};

	/* On TB520FU (Lapis), WL2868C camera PMIC enable is GPIO 5 */
	camera_pmic_en_default: camera-pmic-en-default-state {
		pins = "gpio5";
		function = "gpio";
		drive-strength = <2>;
		bias-disable;
		output-high;
	};

	/* Lenovo Pogo-Pin Keyboard UART10 (qupv3_id_1 SE2 @ 0x888000) */
	qup_uart10_default: qup-uart10-default-state {
		tx-pins {
			pins = "gpio10";
			function = "qup2_se2";
			drive-strength = <2>;
			bias-pull-up;
		};

		rx-pins {
			pins = "gpio11";
			function = "qup2_se2";
			drive-strength = <2>;
			bias-disable;
		};
	};

	kb_pins_default: kb-pins-default-state {
		power-en-pins {
			pins = "gpio173";
			function = "gpio";
			drive-strength = <2>;
			bias-disable;
		};

		wakeup-pins {
			pins = "gpio171";
			function = "gpio";
			drive-strength = <2>;
			bias-disable;
		};

		plug-pins {
			pins = "gpio198";
			function = "gpio";
			drive-strength = <2>;
			bias-disable;
		};
	};

	spkr_2_sd_n_active: spkr-2-sd-n-active-state {
		pins = "gpio77";
		function = "gpio";
		drive-strength = <16>;
		bias-disable;
		output-low;
	};

	tdm1_clk_active: tdm1-clk-active-state {
		pins = "gpio121";
		function = "i2s1_sck";
		drive-strength = <8>;
		bias-disable;
		output-high;
	};

	tdm1_clk_sleep: tdm1-clk-sleep-state {
		pins = "gpio121";
		function = "gpio";
		drive-strength = <2>;
		bias-pull-down;
		input-enable;
	};

	tdm1_ws_active: tdm1-ws-active-state {
		pins = "gpio123";
		function = "i2s1_ws";
		drive-strength = <8>;
		bias-disable;
		output-high;
	};

	tdm1_ws_sleep: tdm1-ws-sleep-state {
		pins = "gpio123";
		function = "gpio";
		drive-strength = <2>;
		bias-pull-down;
		input-enable;
	};

	tdm1_din_active: tdm1-din-active-state {
		pins = "gpio122";
		function = "i2s1_data0";
		drive-strength = <8>;
		bias-disable;
	};

	tdm1_din_sleep: tdm1-din-sleep-state {
		pins = "gpio122";
		function = "gpio";
		drive-strength = <2>;
		bias-pull-down;
		input-enable;
	};

	tdm1_dout_active: tdm1-dout-active-state {
		pins = "gpio124";
		function = "i2s1_data1";
		drive-strength = <8>;
		bias-disable;
	};

	tdm1_dout_sleep: tdm1-dout-sleep-state {
		pins = "gpio124";
		function = "gpio";
		drive-strength = <2>;
		bias-pull-down;
		input-enable;
	};

	ts_irq: ts-irq-state {
		pins = "gpio162";
		function = "gpio";
		drive-strength = <8>;
		bias-pull-up;
		output-disable;
	};

	ts_reset: ts-reset-state {
		pins = "gpio161";
		function = "gpio";
		drive-strength = <8>;
		bias-pull-up;
	};

	wcd_default: wcd-reset-n-active-state {
		pins = "gpio107";
		function = "gpio";
		drive-strength = <16>;
		bias-disable;
		output-low;
	};

	wlan_en: wlan-en-state {
		pins = "gpio16";
		function = "gpio";
		drive-strength = <8>;
		bias-pull-down;
	};

	wlan_sw_ctrl_default: wlan-sw-ctrl-default-state {
		pins = "gpio18", "gpio19";
		function = "gpio";
		drive-strength = <2>;
		bias-disable;
		output-high;
	};
};

&uart14 {
	status = "okay";

	bluetooth {
		compatible = "qcom,wcn7850-bt";
		firmware-name = "hmtnv20_Lapis.bin", "hmtbtfw20.tlv";
		local-bd-address = [33 3f 12 7f 03 00];

		vddrfacmn-supply = <&vreg_pmu_rfa_cmn>;
		vddaon-supply = <&vreg_pmu_aon_0p59>;
		vddwlcx-supply = <&vreg_pmu_wlcx_0p8>;
		vddwlmx-supply = <&vreg_pmu_wlmx_0p85>;
		vddrfa0p8-supply = <&vreg_pmu_rfa_0p8>;
		vddrfa1p2-supply = <&vreg_pmu_rfa_1p2>;
		vddrfa1p8-supply = <&vreg_pmu_rfa_1p8>;

		max-speed = <3200000>;
	};
};

&q6apmbedai {
	clocks = <&q6prmcc LPASS_CLK_ID_SEC_TDM_IBIT LPASS_CLK_ATTRIBUTE_COUPLE_NO>,
		 <&q6prmcc LPASS_CLK_ID_SEC_TDM_EBIT LPASS_CLK_ATTRIBUTE_COUPLE_NO>,
		 <&q6prmcc LPASS_CLK_ID_SEC_MI2S_IBIT LPASS_CLK_ATTRIBUTE_COUPLE_NO>,
		 <&q6prmcc LPASS_CLK_ID_SEC_MI2S_EBIT LPASS_CLK_ATTRIBUTE_COUPLE_NO>,
		 <&q6prmcc LPASS_HW_MACRO_VOTE LPASS_CLK_ATTRIBUTE_COUPLE_NO>,
		 <&q6prmcc LPASS_HW_DCODEC_VOTE LPASS_CLK_ATTRIBUTE_COUPLE_NO>;
	clock-names = "sec-tdm-ibit",
		      "sec-tdm-ebit",
		      "sec-mi2s-ibit",
		      "sec-mi2s-ebit",
		      "lpass-macro",
		      "lpass-dcodec";
};

&uart15 {
	status = "okay";
};

&ufs_mem_hc {
	reset-gpios = <&tlmm 210 GPIO_ACTIVE_LOW>;

	vcc-supply = <&vreg_l17b_2p5>;
	vcc-max-microamp = <1300000>;
	vccq-supply = <&vreg_l1c_1p2>;
	vccq-max-microamp = <1200000>;

	status = "okay";
};

&ufs_mem_phy {
	vdda-phy-supply = <&vreg_l1d_0p88>;
	vdda-pll-supply = <&vreg_l3i_1p2>;

	status = "okay";
};

&usb_1 {
	dr_mode = "otg";
	usb-role-switch;
	role-switch-default-mode = "host";
	qcom,select-utmi-as-pipe-clk;
	qcom,host-ss-powerup-quirk;
	qcom,host-usb2-phy-reinit-quirk;

	status = "okay";
};

&usb_1_dwc3_hs {
	remote-endpoint = <&pmic_glink_hs_in>;
};

&usb_1_hsphy {
	vdd-supply = <&vreg_l1i_0p88>;
	vdda12-supply = <&vreg_l3i_1p2>;

	phys = <&pm8550b_eusb2_repeater>;

	status = "okay";
};

&usb_dp_qmpphy {
	vdda-phy-supply = <&vreg_l3i_1p2>;
	vdda-pll-supply = <&vreg_l3g_0p91>;

	status = "okay";
};

&usb_dp_qmpphy_out {
	remote-endpoint = <&redriver_ss_in>;
};

&xo_board {
	clock-frequency = <76800000>;
};

/* Camera subsystem: Rear main (CSIPHY4), Rear macro (CSIPHY1), Front (CSIPHY0) */
&camss {
	vdd-csiphy01-0p9-supply = <&vreg_l2i_0p88>;
	vdd-csiphy01-1p2-supply = <&vreg_l3i_1p2>;
	vdd-csiphy24-0p9-supply = <&vreg_l2i_0p88>;
	vdd-csiphy24-1p2-supply = <&vreg_l3i_1p2>;
	vdd-csiphy35-0p9-supply = <&vreg_l2i_0p88>;
	vdd-csiphy35-1p2-supply = <&vreg_l3i_1p2>;
	status = "okay";

	ports {
		port@0 {
			reg = <0>;

			csiphy0_ep: endpoint {
				data-lanes = <0 1 2 3>;
				remote-endpoint = <&sc820cs_ep>;
			};
		};

		port@1 {
			reg = <1>;

			csiphy1_ep: endpoint {
				data-lanes = <0>;
				remote-endpoint = <&sc202cs_ep>;
			};
		};

		port@4 {
			reg = <4>;

			csiphy4_ep: endpoint {
				data-lanes = <0 1 2 3>;
				remote-endpoint = <&gc13a0_ep>;
			};
		};
	};
};

&cci0 {
	assigned-clocks = <&camcc CAM_CC_CAMNOC_AXI_NRT_CLK>,
			  <&camcc CAM_CC_CPAS_AHB_CLK>,
			  <&camcc CAM_CC_CCI_0_CLK_SRC>;
	assigned-clock-rates = <300000000>, <80000000>, <37500000>;

	status = "okay";
};

&cci0_i2c0 {
	camera@11 {
		compatible = "galaxycore,gc13a0";
		reg = <0x11>;

		pinctrl-0 = <&cam0_default>, <&cam0_reset_default>;
		pinctrl-names = "default";
		reset-gpios = <&tlmm 7 GPIO_ACTIVE_LOW>;

		clocks = <&camcc CAM_CC_MCLK0_CLK>;
		assigned-clocks = <&camcc CAM_CC_MCLK0_CLK>;
		assigned-clock-rates = <19200000>;

		avdd-supply = <&cam_ldo4_2p8>;
		dovdd-supply = <&cam_ldo3_1p8>;
		dvdd-supply = <&cam_ldo1_1p2>;
		lens-focus = <&gc13a0_vcm>;
		flash-leds = <&pm8550_flash_yellow &pm8550_flash_white>;

		orientation = <1>;
		rotation = <90>;

		port {
			gc13a0_ep: endpoint {
				data-lanes = <0 1 2 3>;
				link-frequencies = /bits/ 64 <560000000>;
				remote-endpoint = <&csiphy4_ep>;
			};
		};
	};

	gc13a0_vcm: camera-lens@c {
		compatible = "giantec,gt9772b";
		reg = <0x0c>;
		vin-supply = <&cam_ldo5_2p78>;
		vdd-supply = <&cam_ldo5_2p78>;
	};
};

&cci0_i2c1 {
	camera@36 {
		compatible = "smartsens,sc202cs";
		reg = <0x36>;

		pinctrl-0 = <&cam1_default>, <&cam2_reset_default>;
		pinctrl-names = "default";
		reset-gpios = <&tlmm 15 GPIO_ACTIVE_LOW>;

		clocks = <&camcc CAM_CC_MCLK1_CLK>;
		assigned-clocks = <&camcc CAM_CC_MCLK1_CLK>;
		assigned-clock-rates = <19200000>;

		ldo7-supply = <&cam_ldo7_2p024>;
		ldo6-supply = <&cam_ldo6_2p78>;

		orientation = <1>;
		rotation = <90>;

		port {
			sc202cs_ep: endpoint {
				data-lanes = <0>;
				link-frequencies = /bits/ 64 <560000000>;
				remote-endpoint = <&csiphy1_ep>;
			};
		};
	};
};

&cci1 {
	assigned-clocks = <&camcc CAM_CC_CAMNOC_AXI_NRT_CLK>,
			  <&camcc CAM_CC_CPAS_AHB_CLK>,
			  <&camcc CAM_CC_CCI_1_CLK_SRC>;
	assigned-clock-rates = <300000000>, <80000000>, <37500000>;
	pinctrl-0 = <&cci1_0_default>;
	pinctrl-1 = <&cci1_0_sleep>;

	status = "okay";
};

&cci1_i2c0 {
	clock-frequency = <100000>;

	camera@36 {
		compatible = "smartsens,sc820cs";
		reg = <0x36>;

		pinctrl-0 = <&cam3_default>, <&cam1_reset_default>;
		pinctrl-names = "default";
		reset-gpios = <&tlmm 109 GPIO_ACTIVE_LOW>;

		clocks = <&camcc CAM_CC_MCLK3_CLK>;
		assigned-clocks = <&camcc CAM_CC_MCLK3_CLK>;
		assigned-clock-rates = <19200000>;

		ldo7-supply = <&cam_ldo7_2p024>;
		ldo2-supply = <&cam_ldo2_1p31>;
		ldo3-supply = <&cam_ldo3_1p8>;

		orientation = <0>;
		rotation = <270>;

		port {
			sc820cs_ep: endpoint {
				data-lanes = <0 1 2 3>;
				link-frequencies = /bits/ 64 <364800000>;
				remote-endpoint = <&csiphy0_ep>;
			};
		};
	};
};
